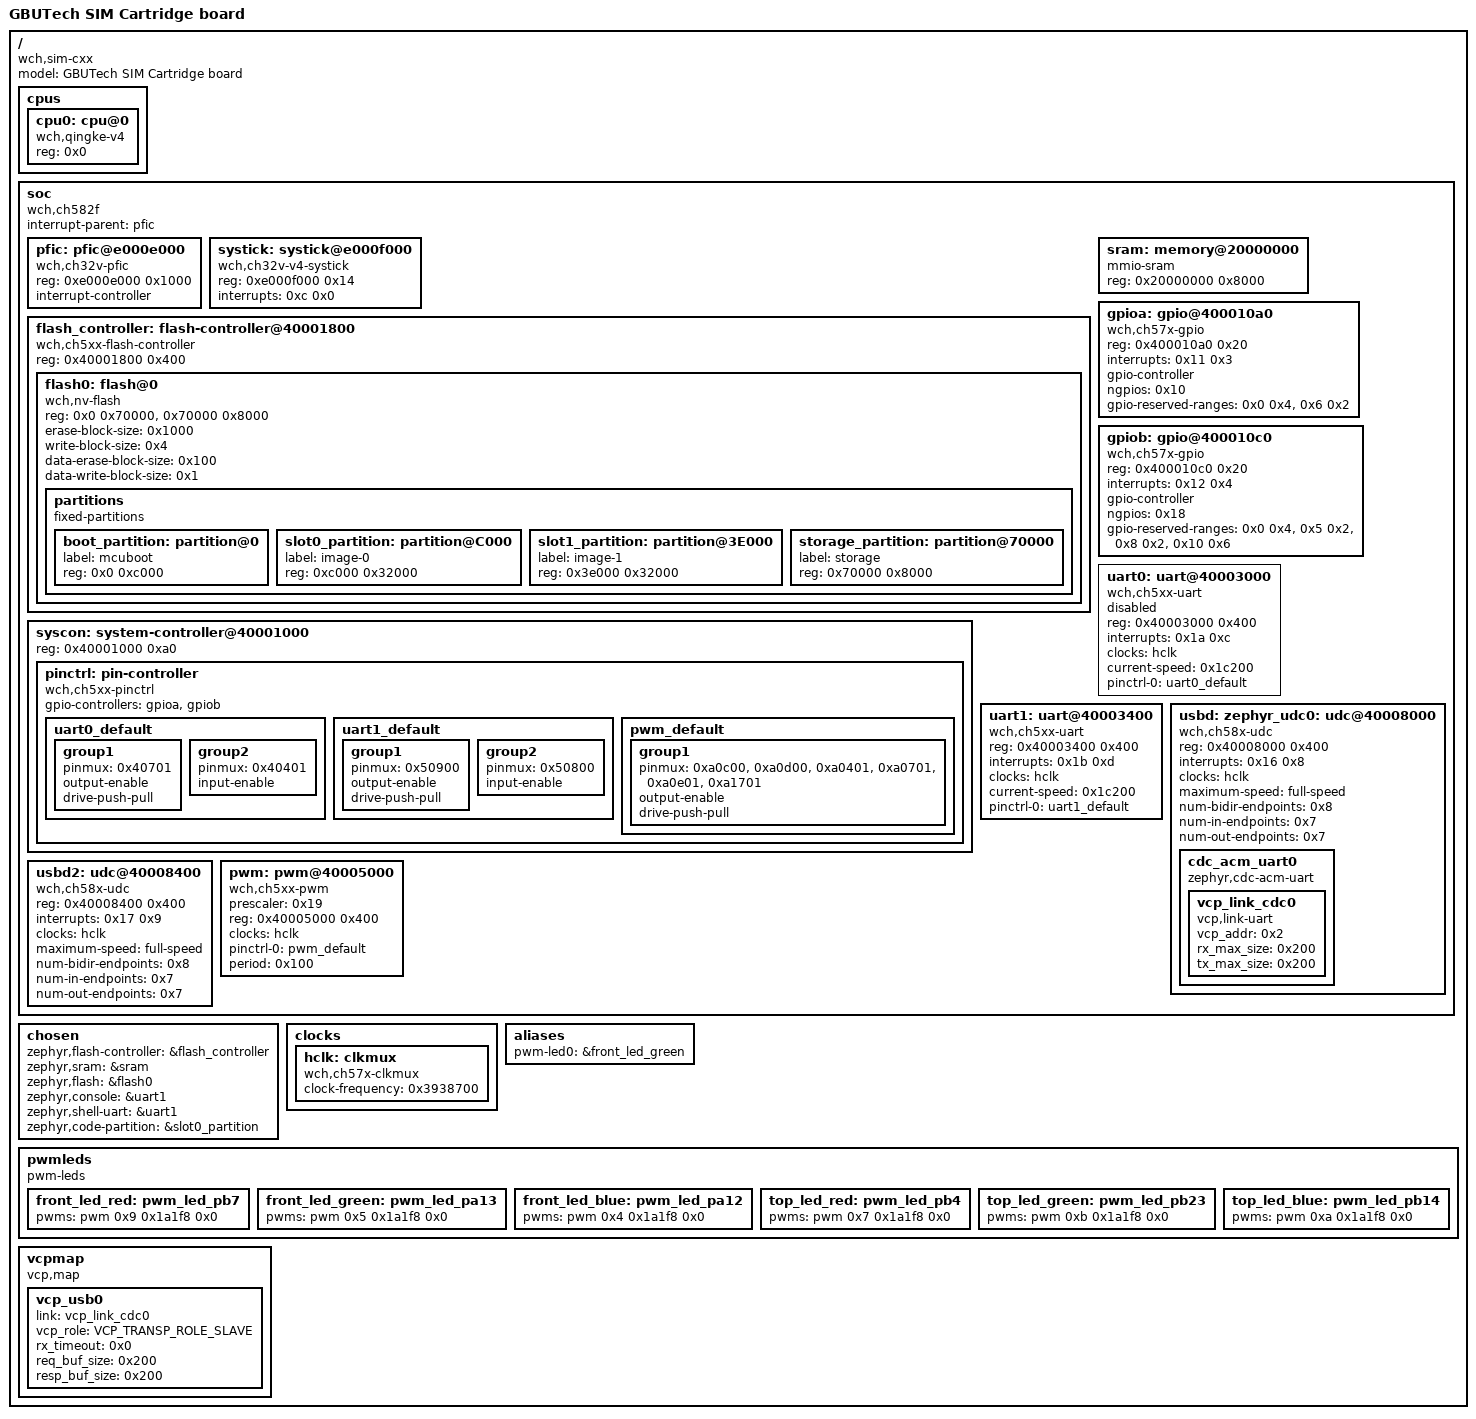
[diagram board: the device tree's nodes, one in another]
/dts-v1/;

/ {
	model = "GBUTech SIM Cartridge board";
	compatible = "wch,sim-cxx";
	cpus {
		#address-cells = < 0x1 >;
		#size-cells = < 0x0 >;
		cpu0: cpu@0 {
			compatible = "wch,qingke-v4";
			reg = < 0x0 >;
		};
	};
	soc {
		compatible = "wch,ch582f";
		#address-cells = < 0x1 >;
		#size-cells = < 0x1 >;
		interrupt-parent = < &pfic >;
		pfic: pfic@e000e000 {
			compatible = "wch,ch32v-pfic";
			reg = < 0xe000e000 0x1000 >;
			interrupt-controller;
			#interrupt-cells = < 0x2 >;
			phandle = < 0x1 >;
		};
		systick: systick@e000f000 {
			compatible = "wch,ch32v-v4-systick";
			reg = < 0xe000f000 0x14 >;
			interrupts = < 0xc 0x0 >;
		};
		flash_controller: flash-controller@40001800 {
			compatible = "wch,ch5xx-flash-controller";
			reg = < 0x40001800 0x400 >;
			#address-cells = < 0x1 >;
			#size-cells = < 0x1 >;
			flash0: flash@0 {
				compatible = "wch,nv-flash", "soc-nv-flash";
				reg = < 0x0 0x70000 >, < 0x70000 0x8000 >;
				reg-names = "code_flash", "data_flash";
				erase-block-size = < 0x1000 >;
				write-block-size = < 0x4 >;
				data-erase-block-size = < 0x100 >;
				data-write-block-size = < 0x1 >;
				partitions {
					compatible = "fixed-partitions";
					#address-cells = < 0x1 >;
					#size-cells = < 0x1 >;
					boot_partition: partition@0 {
						label = "mcuboot";
						reg = < 0x0 0xc000 >;
					};
					slot0_partition: partition@C000 {
						label = "image-0";
						reg = < 0xc000 0x32000 >;
					};
					slot1_partition: partition@3E000 {
						label = "image-1";
						reg = < 0x3e000 0x32000 >;
					};
					storage_partition: partition@70000 {
						label = "storage";
						reg = < 0x70000 0x8000 >;
					};
				};
			};
		};
		sram: memory@20000000 {
			compatible = "mmio-sram";
			reg = < 0x20000000 0x8000 >;
		};
		syscon: system-controller@40001000 {
			reg = < 0x40001000 0xa0 >;
			pinctrl: pin-controller {
				compatible = "wch,ch5xx-pinctrl";
				gpio-controllers = < &gpioa >, < &gpiob >;
				uart0_default: uart0_default {
					phandle = < 0x5 >;
					group1 {
						pinmux = < 0x40701 >;
						output-enable;
						drive-push-pull;
					};
					group2 {
						pinmux = < 0x40401 >;
						input-enable;
					};
				};
				uart1_default: uart1_default {
					phandle = < 0x6 >;
					group1 {
						pinmux = < 0x50900 >;
						output-enable;
						drive-push-pull;
					};
					group2 {
						pinmux = < 0x50800 >;
						input-enable;
					};
				};
				pwm_default: pwm_default {
					phandle = < 0x7 >;
					group1 {
						pinmux = < 0xa0c00 >, < 0xa0d00 >, < 0xa0401 >, < 0xa0701 >, < 0xa0e01 >, < 0xa1701 >;
						output-enable;
						drive-push-pull;
					};
				};
			};
		};
		gpioa: gpio@400010a0 {
			compatible = "wch,ch57x-gpio";
			reg = < 0x400010a0 0x20 >;
			interrupts = < 0x11 0x3 >;
			gpio-controller;
			#gpio-cells = < 0x2 >;
			ngpios = < 0x10 >;
			gpio-reserved-ranges = < 0x0 0x4 >, < 0x6 0x2 >;
			phandle = < 0x2 >;
		};
		gpiob: gpio@400010c0 {
			compatible = "wch,ch57x-gpio";
			reg = < 0x400010c0 0x20 >;
			interrupts = < 0x12 0x4 >;
			gpio-controller;
			#gpio-cells = < 0x2 >;
			ngpios = < 0x18 >;
			gpio-reserved-ranges = < 0x0 0x4 >, < 0x5 0x2 >, < 0x8 0x2 >, < 0x10 0x6 >;
			phandle = < 0x3 >;
		};
		uart0: uart@40003000 {
			compatible = "wch,ch5xx-uart";
			reg = < 0x40003000 0x400 >;
			interrupts = < 0x1a 0xc >;
			clocks = < &hclk >;
			status = "disabled";
			current-speed = < 0x1c200 >;
			pinctrl-0 = < &uart0_default >;
			pinctrl-names = "default";
		};
		uart1: uart@40003400 {
			compatible = "wch,ch5xx-uart";
			reg = < 0x40003400 0x400 >;
			interrupts = < 0x1b 0xd >;
			clocks = < &hclk >;
			status = "okay";
			current-speed = < 0x1c200 >;
			pinctrl-0 = < &uart1_default >;
			pinctrl-names = "default";
		};
		usbd: zephyr_udc0: udc@40008000 {
			compatible = "wch,ch58x-udc";
			reg = < 0x40008000 0x400 >;
			interrupts = < 0x16 0x8 >;
			clocks = < &hclk >;
			maximum-speed = "full-speed";
			num-bidir-endpoints = < 0x8 >;
			num-in-endpoints = < 0x7 >;
			num-out-endpoints = < 0x7 >;
			status = "okay";
			cdc_acm_uart0: cdc_acm_uart0 {
				compatible = "zephyr,cdc-acm-uart";
				vcp_link_cdc0: vcp_link_cdc0 {
					compatible = "vcp,link-uart";
					vcp_addr = < 0x2 >;
					rx_max_size = < 0x200 >;
					tx_max_size = < 0x200 >;
					phandle = < 0x9 >;
				};
			};
		};
		usbd2: udc@40008400 {
			compatible = "wch,ch58x-udc";
			reg = < 0x40008400 0x400 >;
			interrupts = < 0x17 0x9 >;
			clocks = < &hclk >;
			maximum-speed = "full-speed";
			num-bidir-endpoints = < 0x8 >;
			num-in-endpoints = < 0x7 >;
			num-out-endpoints = < 0x7 >;
		};
		pwm: pwm@40005000 {
			compatible = "wch,ch5xx-pwm";
			#pwm-cells = < 0x3 >;
			prescaler = < 0x19 >;
			reg = < 0x40005000 0x400 >;
			clocks = < &hclk >;
			status = "okay";
			pinctrl-0 = < &pwm_default >;
			pinctrl-names = "default";
			period = < 0x100 >;
			phandle = < 0x8 >;
		};
	};
	chosen {
		zephyr,flash-controller = &flash_controller;
		zephyr,sram = &sram;
		zephyr,flash = &flash0;
		zephyr,console = &uart1;
		zephyr,shell-uart = &uart1;
		zephyr,code-partition = &slot0_partition;
	};
	clocks {
		hclk: clkmux {
			compatible = "wch,ch57x-clkmux";
			clock-frequency = < 0x3938700 >;
			#clock-cells = < 0x0 >;
			phandle = < 0x4 >;
		};
	};
	aliases {
		pwm-led0 = &front_led_green;
	};
	pwmleds {
		compatible = "pwm-leds";
		front_led_red: pwm_led_pb7 {
			pwms = < &pwm 0x9 0x1a1f8 0x0 >;
		};
		front_led_green: pwm_led_pa13 {
			pwms = < &pwm 0x5 0x1a1f8 0x0 >;
		};
		front_led_blue: pwm_led_pa12 {
			pwms = < &pwm 0x4 0x1a1f8 0x0 >;
		};
		top_led_red: pwm_led_pb4 {
			pwms = < &pwm 0x7 0x1a1f8 0x0 >;
		};
		top_led_green: pwm_led_pb23 {
			pwms = < &pwm 0xb 0x1a1f8 0x0 >;
		};
		top_led_blue: pwm_led_pb14 {
			pwms = < &pwm 0xa 0x1a1f8 0x0 >;
		};
	};
	vcpmap {
		compatible = "vcp,map";
		vcp_usb0: vcp_usb0 {
			link = < &vcp_link_cdc0 >;
			vcp_role = "VCP_TRANSP_ROLE_SLAVE";
			rx_timeout = < 0x0 >;
			req_buf_size = < 0x200 >;
			resp_buf_size = < 0x200 >;
		};
	};
};
